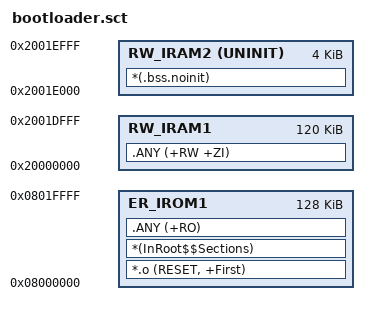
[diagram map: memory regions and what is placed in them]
LR_IROM1 0x08000000 0x00020000  {
  ER_IROM1 0x08000000 0x00020000  {
    *.o (RESET, +First)
    *(InRoot$$Sections)
    .ANY (+RO)
  }
  RW_IRAM1 0x20000000 0x0001E000  {
    .ANY (+RW +ZI)
  }
  RW_IRAM2 0x2001E000 UNINIT 0x00001000 {
    *(.bss.noinit)
  }
}
